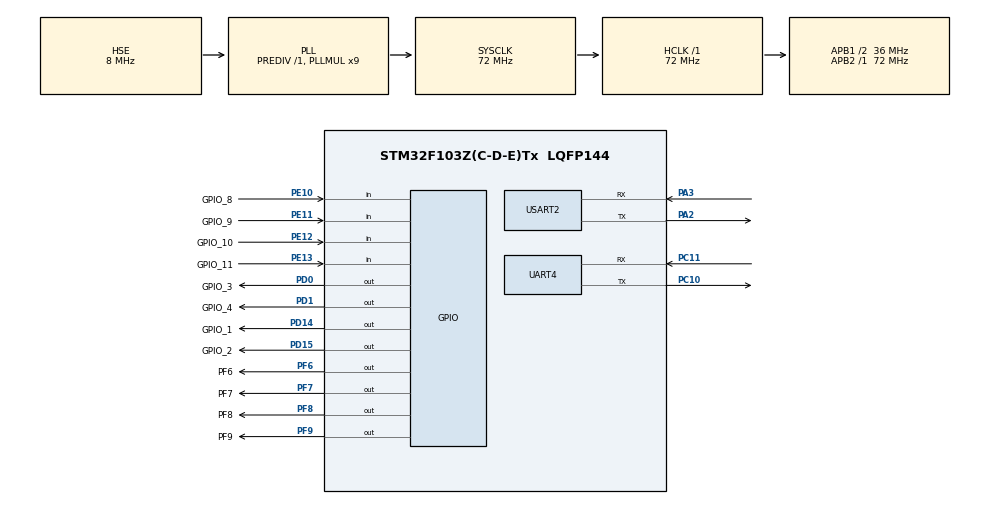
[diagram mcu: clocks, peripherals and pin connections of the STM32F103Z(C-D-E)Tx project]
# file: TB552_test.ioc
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Dma.Request0=USART2_RX
Dma.USART2_RX.0.Direction=DMA_PERIPH_TO_MEMORY
Dma.USART2_RX.0.Instance=DMA1_Channel6
Dma.USART2_RX.0.MemDataAlignment=DMA_MDATAALIGN_BYTE
Dma.USART2_RX.0.MemInc=DMA_MINC_ENABLE
Dma.USART2_RX.0.Mode=DMA_NORMAL
Dma.USART2_RX.0.PeriphDataAlignment=DMA_PDATAALIGN_BYTE
Dma.USART2_RX.0.PeriphInc=DMA_PINC_DISABLE
Dma.USART2_RX.0.Priority=DMA_PRIORITY_LOW
Mcu.Family=STM32F1
Mcu.Name=STM32F103Z(C-D-E)Tx
Mcu.Package=LQFP144
NVIC.DMA1_Channel6_IRQn=true\:0\:0\:false\:false\:true\:false
NVIC.PriorityGroup=NVIC_PRIORITYGROUP_1
NVIC.UART4_IRQn=true\:1\:0\:true\:false\:true\:true
NVIC.USART2_IRQn=true\:0\:0\:false\:false\:true\:true
OSC_IN.Mode=HSE-External-Oscillator
OSC_IN.Signal=RCC_OSC_IN
OSC_OUT.Mode=HSE-External-Oscillator
OSC_OUT.Signal=RCC_OSC_OUT
PA13.Mode=Serial_Wire
PA13.Signal=SYS_JTMS-SWDIO
PA14.Mode=Serial_Wire
PA14.Signal=SYS_JTCK-SWCLK
PA2.Mode=Asynchronous
PA2.Signal=USART2_TX
PA3.Mode=Asynchronous
PA3.Signal=USART2_RX
PC10.Mode=Asynchronous
PC10.Signal=UART4_TX
PC11.Mode=Asynchronous
PC11.Signal=UART4_RX
PD0.GPIO_Label=GPIO_3
PD0.PinState=GPIO_PIN_RESET
PD0.Signal=GPIO_Output
PD1.GPIO_Label=GPIO_4
PD1.PinState=GPIO_PIN_RESET
PD1.Signal=GPIO_Output
PD14.GPIO_Label=GPIO_1
PD14.PinState=GPIO_PIN_RESET
PD14.Signal=GPIO_Output
PD15.GPIO_Label=GPIO_2
PD15.PinState=GPIO_PIN_RESET
PD15.Signal=GPIO_Output
PE10.GPIO_Label=GPIO_8
PE10.Signal=GPIO_Input
PE11.GPIO_Label=GPIO_9
PE11.Signal=GPIO_Input
PE12.GPIO_Label=GPIO_10
PE12.Signal=GPIO_Input
PE13.GPIO_Label=GPIO_11
PE13.Signal=GPIO_Input
PF6.GPIO_Label=PF6
PF6.PinState=GPIO_PIN_SET
PF6.Signal=GPIO_Output
PF7.GPIO_Label=PF7
PF7.PinState=GPIO_PIN_SET
PF7.Signal=GPIO_Output
PF8.GPIO_Label=PF8
PF8.PinState=GPIO_PIN_SET
PF8.Signal=GPIO_Output
PF9.GPIO_Label=PF9
PF9.PinState=GPIO_PIN_SET
PF9.Signal=GPIO_Output
ProjectManager.HeapSize=0x200
ProjectManager.StackSize=0x400
ProjectManager.TargetToolchain=MDK-ARM V5
RCC.AHBFreq_Value=72000000
RCC.APB1CLKDivider=RCC_HCLK_DIV2
RCC.APB1Freq_Value=36000000
RCC.APB1TimFreq_Value=72000000
RCC.APB2Freq_Value=72000000
RCC.APB2TimFreq_Value=72000000
RCC.HCLKFreq_Value=72000000
RCC.PLLMUL=RCC_PLL_MUL9
RCC.PLLSourceVirtual=RCC_PLLSOURCE_HSE
RCC.SYSCLKFreq_VALUE=72000000
RCC.SYSCLKSource=RCC_SYSCLKSOURCE_PLLCLK
RCC.USBFreq_Value=72000000
UART4.VirtualMode=Asynchronous
USART2.VirtualMode=VM_ASYNC
board=custom

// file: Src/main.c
/**
  ******************************************************************************
  * @file           : main.c
  * @brief          : Main program body
  ******************************************************************************
  ** This notice applies to any and all portions of this file
  * that are not between comment pairs USER CODE BEGIN and
  * USER CODE END. Other portions of this file, whether
  * inserted by the user or by software development tools
  * are owned by their respective copyright owners.
  *
  * COPYRIGHT(c) 2018 STMicroelectronics
  *
  * Redistribution and use in source and binary forms, with or without modification,
  * are permitted provided that the following conditions are met:
  *   1. Redistributions of source code must retain the above copyright notice,
  *      this list of conditions and the following disclaimer.
  *   2. Redistributions in binary form must reproduce the above copyright notice,
  *      this list of conditions and the following disclaimer in the documentation
  *      and/or other materials provided with the distribution.
  *   3. Neither the name of STMicroelectronics nor the names of its contributors
  *      may be used to endorse or promote products derived from this software
  *      without specific prior written permission.
  *
  * THIS SOFTWARE IS PROVIDED BY THE COPYRIGHT HOLDERS AND CONTRIBUTORS "AS IS"
  * AND ANY EXPRESS OR IMPLIED WARRANTIES, INCLUDING, BUT NOT LIMITED TO, THE
  * IMPLIED WARRANTIES OF MERCHANTABILITY AND FITNESS FOR A PARTICULAR PURPOSE ARE
  * DISCLAIMED. IN NO EVENT SHALL THE COPYRIGHT HOLDER OR CONTRIBUTORS BE LIABLE
  * FOR ANY DIRECT, INDIRECT, INCIDENTAL, SPECIAL, EXEMPLARY, OR CONSEQUENTIAL
  * DAMAGES (INCLUDING, BUT NOT LIMITED TO, PROCUREMENT OF SUBSTITUTE GOODS OR
  * SERVICES; LOSS OF USE, DATA, OR PROFITS; OR BUSINESS INTERRUPTION) HOWEVER
  * CAUSED AND ON ANY THEORY OF LIABILITY, WHETHER IN CONTRACT, STRICT LIABILITY,
  * OR TORT (INCLUDING NEGLIGENCE OR OTHERWISE) ARISING IN ANY WAY OUT OF THE USE
  * OF THIS SOFTWARE, EVEN IF ADVISED OF THE POSSIBILITY OF SUCH DAMAGE.
  *
  ******************************************************************************
  */
#include "main.h"
#include "stm32f1xx_hal.h"

/* USER CODE BEGIN Includes */
#include "tb552_test.h"
/* USER CODE END Includes */

UART_HandleTypeDef huart4;
UART_HandleTypeDef huart2;
DMA_HandleTypeDef hdma_usart2_rx;

/* USER CODE BEGIN PV */
/* Private variables ---------------------------------------------------------*/

/* USER CODE END PV */

void SystemClock_Config(void);
static void MX_GPIO_Init(void);
static void MX_DMA_Init(void);
static void MX_USART2_UART_Init(void);
static void MX_UART4_Init(void);

/* USER CODE BEGIN PFP */
/* Private function prototypes -----------------------------------------------*/

/* USER CODE END PFP */

/* USER CODE BEGIN 0 */

/*	自己添加代码部分	*/
volatile uint8_t rx_len=0;							//接收数据长度
volatile uint8_t recv_end_flag=0;				//接收完成标记位
uint8_t  rx_buffer[100];								//接收缓存
char 		 BUFFER_SIZE=100;								//不定长数据的最大长度，设置为200则最大长度为200

/* USER CODE END 0 */

int main(void)
{

  /* MCU Configuration----------------------------------------------------------*/

  /* Reset of all peripherals, Initializes the Flash interface and the Systick. */
  HAL_Init();

  /* Configure the system clock */
  SystemClock_Config();

  /* Initialize all configured peripherals */
  MX_GPIO_Init();
  MX_DMA_Init();
  MX_USART2_UART_Init();
  MX_UART4_Init();

  /* Infinite loop */
  while (1)
  {

  /* USER CODE BEGIN 3 */
		comm();
  }
  /* USER CODE END 3 */

}

void SystemClock_Config(void)
{

  RCC_OscInitTypeDef RCC_OscInitStruct;
  RCC_ClkInitTypeDef RCC_ClkInitStruct;

    /**Initializes the CPU, AHB and APB busses clocks
    */
  RCC_OscInitStruct.OscillatorType = RCC_OSCILLATORTYPE_HSE;
  RCC_OscInitStruct.HSEState = RCC_HSE_ON;
  RCC_OscInitStruct.HSEPredivValue = RCC_HSE_PREDIV_DIV1;
  RCC_OscInitStruct.HSIState = RCC_HSI_ON;
  RCC_OscInitStruct.PLL.PLLState = RCC_PLL_ON;
  RCC_OscInitStruct.PLL.PLLSource = RCC_PLLSOURCE_HSE;
  RCC_OscInitStruct.PLL.PLLMUL = RCC_PLL_MUL9;
  if (HAL_RCC_OscConfig(&RCC_OscInitStruct) != HAL_OK)
  {
    _Error_Handler(__FILE__, __LINE__);
  }

    /**Initializes the CPU, AHB and APB busses clocks
    */
  RCC_ClkInitStruct.ClockType = RCC_CLOCKTYPE_HCLK|RCC_CLOCKTYPE_SYSCLK
                              |RCC_CLOCKTYPE_PCLK1|RCC_CLOCKTYPE_PCLK2;
  RCC_ClkInitStruct.SYSCLKSource = RCC_SYSCLKSOURCE_PLLCLK;
  RCC_ClkInitStruct.AHBCLKDivider = RCC_SYSCLK_DIV1;
  RCC_ClkInitStruct.APB1CLKDivider = RCC_HCLK_DIV2;
  RCC_ClkInitStruct.APB2CLKDivider = RCC_HCLK_DIV1;

  if (HAL_RCC_ClockConfig(&RCC_ClkInitStruct, FLASH_LATENCY_2) != HAL_OK)
  {
    _Error_Handler(__FILE__, __LINE__);
  }

    /**Configure the Systick interrupt time
    */
  HAL_SYSTICK_Config(HAL_RCC_GetHCLKFreq()/1000);

    /**Configure the Systick
    */
  HAL_SYSTICK_CLKSourceConfig(SYSTICK_CLKSOURCE_HCLK);

  /* SysTick_IRQn interrupt configuration */
  HAL_NVIC_SetPriority(SysTick_IRQn, 0, 0);
}

/* UART4 init function */
static void MX_UART4_Init(void)
{

  huart4.Instance = UART4;
  huart4.Init.BaudRate = 115200;
  huart4.Init.WordLength = UART_WORDLENGTH_8B;
  huart4.Init.StopBits = UART_STOPBITS_1;
  huart4.Init.Parity = UART_PARITY_NONE;
  huart4.Init.Mode = UART_MODE_TX_RX;
  huart4.Init.HwFlowCtl = UART_HWCONTROL_NONE;
  huart4.Init.OverSampling = UART_OVERSAMPLING_16;
  if (HAL_UART_Init(&huart4) != HAL_OK)
  {
    _Error_Handler(__FILE__, __LINE__);
  }

}

/* USART2 init function */
static void MX_USART2_UART_Init(void)
{

  huart2.Instance = USART2;
  huart2.Init.BaudRate = 115200;
  huart2.Init.WordLength = UART_WORDLENGTH_8B;
  huart2.Init.StopBits = UART_STOPBITS_1;
  huart2.Init.Parity = UART_PARITY_NONE;
  huart2.Init.Mode = UART_MODE_TX_RX;
  huart2.Init.HwFlowCtl = UART_HWCONTROL_NONE;
  huart2.Init.OverSampling = UART_OVERSAMPLING_16;
  if (HAL_UART_Init(&huart2) != HAL_OK)
  {
    _Error_Handler(__FILE__, __LINE__);
  }

	/*	自己添加代码部分	*/
	 __HAL_UART_ENABLE_IT(&huart2, UART_IT_IDLE);//使能idle中断
   HAL_UART_Receive_DMA(&huart2,rx_buffer,BUFFER_SIZE);//打开DMA接收，数据存入rx_buffer数组中。

}

static void MX_DMA_Init(void)
{
  /* DMA controller clock enable */
  __HAL_RCC_DMA1_CLK_ENABLE();

  /* DMA interrupt init */
  /* DMA1_Channel6_IRQn interrupt configuration */
  HAL_NVIC_SetPriority(DMA1_Channel6_IRQn, 0, 0);
  HAL_NVIC_EnableIRQ(DMA1_Channel6_IRQn);

}

/** Configure pins as
        * Analog
        * Input
        * Output
        * EVENT_OUT
        * EXTI
*/
static void MX_GPIO_Init(void)
{

  GPIO_InitTypeDef GPIO_InitStruct;

  /* GPIO Ports Clock Enable */
  __HAL_RCC_GPIOF_CLK_ENABLE();
  __HAL_RCC_GPIOA_CLK_ENABLE();
  __HAL_RCC_GPIOE_CLK_ENABLE();
  __HAL_RCC_GPIOD_CLK_ENABLE();
  __HAL_RCC_GPIOC_CLK_ENABLE();

  /*Configure GPIO pin Output Level */
  HAL_GPIO_WritePin(GPIOF, PF6_Pin|PF7_Pin|PF8_Pin|PF9_Pin, GPIO_PIN_SET);

  /*Configure GPIO pin Output Level */
  HAL_GPIO_WritePin(GPIOD, GPIO_1_Pin|GPIO_2_Pin|GPIO_3_Pin|GPIO_4_Pin, GPIO_PIN_RESET);

  /*Configure GPIO pins : PF6_Pin PF7_Pin PF8_Pin PF9_Pin */
  GPIO_InitStruct.Pin = PF6_Pin|PF7_Pin|PF8_Pin|PF9_Pin;
  GPIO_InitStruct.Mode = GPIO_MODE_OUTPUT_PP;
  GPIO_InitStruct.Pull = GPIO_NOPULL;
  GPIO_InitStruct.Speed = GPIO_SPEED_FREQ_LOW;
  HAL_GPIO_Init(GPIOF, &GPIO_InitStruct);

  /*Configure GPIO pins : GPIO_8_Pin GPIO_9_Pin GPIO_10_Pin GPIO_11_Pin */
  GPIO_InitStruct.Pin = GPIO_8_Pin|GPIO_9_Pin|GPIO_10_Pin|GPIO_11_Pin;
  GPIO_InitStruct.Mode = GPIO_MODE_INPUT;
  GPIO_InitStruct.Pull = GPIO_NOPULL;
  HAL_GPIO_Init(GPIOE, &GPIO_InitStruct);

  /*Configure GPIO pins : GPIO_1_Pin GPIO_2_Pin GPIO_3_Pin GPIO_4_Pin */
  GPIO_InitStruct.Pin = GPIO_1_Pin|GPIO_2_Pin|GPIO_3_Pin|GPIO_4_Pin;
  GPIO_InitStruct.Mode = GPIO_MODE_OUTPUT_PP;
  GPIO_InitStruct.Pull = GPIO_NOPULL;
  GPIO_InitStruct.Speed = GPIO_SPEED_FREQ_LOW;
  HAL_GPIO_Init(GPIOD, &GPIO_InitStruct);

}

void _Error_Handler(char *file, int line)
{
  while(1)
  {
  }
}

/************************ (C) COPYRIGHT STMicroelectronics *****END OF FILE****/
